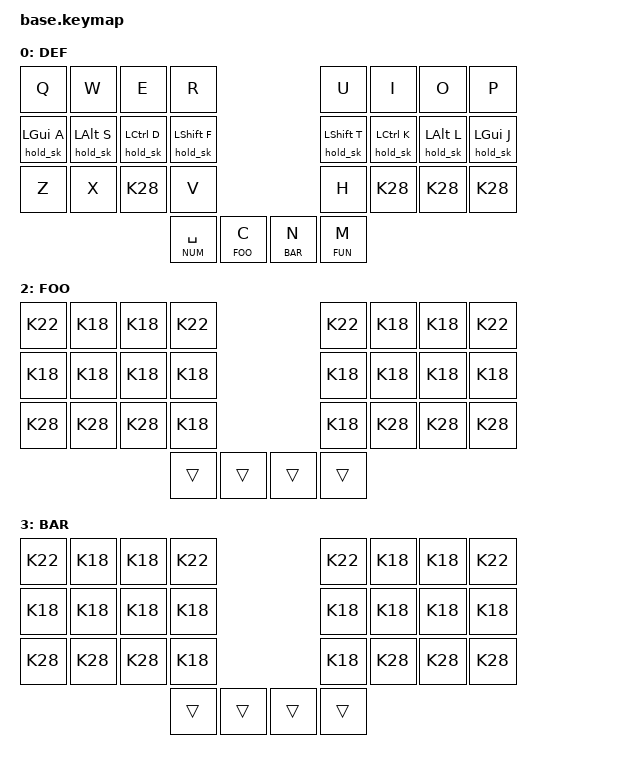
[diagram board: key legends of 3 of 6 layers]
// This file is automatically generated by sh from config/base.keymap

//╭─────────────╮   ╭─────────────╮   ╭─────────────┬───┬─────────────╮   ╭─────────────╮   ╭─────────────╮                                 ╭─────────────╮   ╭─────────────╮   ╭─────────────┬───┬─────────────╮   ╭─────────────╮   ╭─────────────╮
//                   K22               K18               K18               K22                                                                                 K22               K18               K18               K22                  
//├─────────────┤   ╰─────────────╯   ├─────────────┼───┼─────────────┤   ╰─────────────╯   ├─────────────┤                                 ├─────────────┤   ╰─────────────╯   ├─────────────┼───┼─────────────┤   ╰─────────────╯   ├─────────────┤
//├─────────────┤   ╭─────────────┬───┼─────────────┼───┼─────────────┼───┬─────────────╮   ├─────────────┤                                 ├─────────────┤   ╭─────────────┬───┼─────────────┼───┼─────────────┼───┬─────────────╮   ├─────────────┤
//                   K18               K18               K18               K18                                                                                 K18               K18               K18               K18                  
//├─────────────┤   ╰─────────────┴───┴─────────────┴───┴─────────────┴───┼─────────────┤   ├─────────────┤                                 ├─────────────┤   ├─────────────┼───┴─────────────┴───┴─────────────┴───┴─────────────╯   ├─────────────┤
//├─────────────┤   ╭─────────────┬───┬─────────────┬───┬─────────────╮   ├─────────────┤   ├─────────────┤                                 ├─────────────┤   ├─────────────┤   ╭─────────────┬───┬─────────────┬───┬─────────────╮   ├─────────────┤
//                   K28               K28               K28               K18                                                                                 K18               K28               K28               K28                  
//╰─────────────╯   ╰─────────────┴───┴─────────────┴───┴─────────────╯   ╰─────────────╯   ╰─────────────╯                                 ╰─────────────╯   ╰─────────────╯   ╰─────────────┴───┴─────────────┴───┴─────────────╯   ╰─────────────╯
//                                                                        ╭─────────────┬───┬─────────────╮ ╭─────────────────────────────╮ ╭─────────────┬───┬─────────────╮
//                                                                         K18               K18                                             K18               K18
//                                                                        ╰─────────────┴───┴─────────────╯ ╰─────────────────────────────╯ ╰─────────────┴───┴─────────────╯

// NOTE:
// 1. Use double tap instead of modify tap
// 2. Use sticky key instead of hold key
// 3. Never use two finger to type a single key

#include <behaviors.dtsi>
#include <dt-bindings/zmk/bt.h>
#include <dt-bindings/zmk/keys.h>
#include "../../../zmk-nodefree-config/helper.h"

//////////////////////////////
// Global Behavior
//////////////////////////////

#define TAP_MS       200
#define SHORT_TAP_MS 165

&sl {
    release-after-ms = <5000>;
    // quick-release;
};

&sk {
    release-after-ms = <5000>;
    // quick-release;
};

#define TAP_TAP(                                          \
    NAME       ,                                          \
    TAP_ACT    , TAP    ,                                 \
    TAPTAP_ACT , TAPTAP                                   \
    )                                                     \
    ZMK_BEHAVIOR(                                         \
        NAME,                                             \
        tap_dance,                                        \
        tapping-term-ms = <TAP_MS>;                       \
        bindings = <&TAP_ACT TAP> , <&TAPTAP_ACT TAPTAP>; \
    )

#define MAKE_HRM(                         \
    NAME ,                                \
    HOLD , TAP                            \
    )                                     \
    ZMK_BEHAVIOR(                         \
        NAME,                             \
        hold_tap,                         \
        flavor = "balanced";              \
        tapping-term-ms = <TAP_MS>;       \
        quick-tap-ms = <TAP_MS>;          \
        require-prior-idle-ms = <TAP_MS>; \
        bindings = <HOLD>, <TAP>;         \
    )
MAKE_HRM(hold_sk, &sk, &kp)

//////////////////////////////
// Layer Definition
//////////////////////////////

// 主副层，放置非功能键
#define DEF 0
#define NUM 1

// 零时层, 放置临时快捷键
#define FOO 2
#define BAR 3

// 功能层，放置功能快捷键
#define FUN 4

// 控制层
#define BLU 5

//////////////////////////////
// DEF
//////////////////////////////

////////////////////
// combos
////////////////////

ZMK_COMBO(esc         , &kp ESC             , LT3 LT2 , DEF, COMBO_TERM)
ZMK_COMBO(tab         , &kp TAB             , LM3 LM2 , DEF, COMBO_TERM)
ZMK_COMBO(bspc        , &kp BSPC            , RT2 RT3 , DEF, COMBO_TERM)
ZMK_COMBO(enter       , &kp ENTER           , RM2 RM3 , DEF, COMBO_TERM)

//////////

ZMK_COMBO(0           , &kp 0               , LT3 LM3 , DEF , COMBO_TERM)
ZMK_COMBO(y           , &kp Y               , LT2 LM2 , DEF , COMBO_TERM)
ZMK_COMBO(0           , &kp 0               , RT2 RM2 , DEF , COMBO_TERM)
ZMK_COMBO(0           , &kp 0               , RT3 RM3 , DEF , COMBO_TERM)

ZMK_COMBO(g           , &kp G               , LM1 LB1 , DEF , COMBO_TERM)
ZMK_COMBO(b           , &kp B               , RM1 RB1 , DEF , COMBO_TERM)

ZMK_COMBO(z           , &kp Z               , LH1 LH0 , DEF , COMBO_TERM)
ZMK_COMBO(x           , &kp X               , RH0 RH1 , DEF , COMBO_TERM)

////////////////////

ZMK_LAYER(DEF,
//╭─────────────╮   ╭─────────────╮   ╭─────────────┬───┬─────────────╮   ╭─────────────╮   ╭─────────────╮                                 ╭─────────────╮   ╭─────────────╮   ╭─────────────┬───┬─────────────╮   ╭─────────────╮   ╭─────────────╮
                     &kp Q             &kp W             &kp E             &kp R                                                                               &kp U             &kp I             &kp O             &kp P                
//                                                   Esc                                                                                                                                    Backspace
//├─────────────┤   ╰─────────────╯   ├─────────────┼───┼─────────────┤   ╰─────────────╯   ├─────────────┤                                 ├─────────────┤   ╰─────────────╯   ├─────────────┼───┼─────────────┤   ╰─────────────╯   ├─────────────┤
//                                          CMB                Y                                                                                                                      CMB               CMB
//├─────────────┤   ╭─────────────┬───┼─────────────┼───┼─────────────┼───┬─────────────╮   ├─────────────┤                                 ├─────────────┤   ╭─────────────┬───┼─────────────┼───┼─────────────┼───┬─────────────╮   ├─────────────┤
                     &hold_sk LGUI A   &hold_sk LALT S   &hold_sk LCTRL D  &hold_sk LSHFT F                                                                    &hold_sk LSHFT T  &hold_sk LCTRL K  &hold_sk LALT L   &hold_sk LGUI J      
//                                                   TAB                                                                                                                                      Return
//├─────────────┤   ╰─────────────┴───┴─────────────┴───┴─────────────┴───┼─────────────┤   ├─────────────┤                                 ├─────────────┤   ├─────────────┼───┴─────────────┴───┴─────────────┴───┴─────────────╯   ├─────────────┤
//                                                                              CMB                                                                                  B
//├─────────────┤   ╭─────────────┬───┬─────────────┬───┬─────────────╮   ├─────────────┤   ├─────────────┤                                 ├─────────────┤   ├─────────────┤   ╭─────────────┬───┬─────────────┬───┬─────────────╮   ├─────────────┤
                     &kp Z             &kp X             K28               &kp V                                                                               &kp H             K28               K28               K28                  
//╰─────────────╯   ╰─────────────┴───┴─────────────┴───┴─────────────╯   ╰─────────────╯   ╰─────────────╯                                 ╰─────────────╯   ╰─────────────╯   ╰─────────────┴───┴─────────────┴───┴─────────────╯   ╰─────────────╯
//                                                                        ╭─────────────┬───┬─────────────╮ ╭─────────────────────────────╮ ╭─────────────┬───┬─────────────╮
                                                                           &lt NUM SPACE     &lt FOO C                                       &lt BAR N         &lt FUN M
//                                                                        ╰─────────────┴───┴─────────────╯ ╰─────────────────────────────╯ ╰─────────────┴───┴─────────────╯
//                                                                                        Z                                                                 X
)

//////////////////////////////
// NUM
//////////////////////////////

//      NAME        , TAP_ACT , TAP      , TAPTAP_ACT , TAPTAP
TAP_TAP(comma_semi  , kp      , COMMA    , kp         , SEMI     ) // , (б) / ; (ж)
TAP_TAP(dot_colon   , kp      , DOT      , kp         , COLON    ) // . (ю) / :
TAP_TAP(excl_qmark  , kp      , EXCL     , kp         , QMARK    ) // !     / ?
TAP_TAP(apos_aposs  , kp      , APOS     , kp         , LS(APOS) ) // ' (э) / "
TAP_TAP(minus_plus  , kp      , MINUS    , kp         , PLUS     ) // -     / +
TAP_TAP(fslh_star   , kp      , FSLH     , kp         , STAR     ) // /     / *
TAP_TAP(dllr_caret  , kp      , DLLR     , kp         , CARET    ) // $     / ^
TAP_TAP(amps_pipe   , kp      , AMPS     , kp         , PIPE     ) // &     / |
TAP_TAP(under_equal , kp      , UNDER    , kp         , EQUAL    ) // _     / =
TAP_TAP(tilde_grave , kp      , TILDE    , kp         , GRAVE    ) // ~     / `
TAP_TAP(bslh_at     , kp      , BSLH     , kp         , AT       ) // \ (ё) / @
TAP_TAP(hash_prcnt  , kp      , HASH     , kp         , PRCNT    ) // #     / %
TAP_TAP(lt_gt       , kp      , LT       , kp         , GT       ) // <     / >
TAP_TAP(lpar_rpar   , kp      , LPAR     , kp         , RPAR     ) // (     / )
TAP_TAP(lbkt_rbkt   , kp      , LBKT     , kp         , RBKT     ) // [ (х) / ] (ъ)
TAP_TAP(lbrc_rbrc   , kp      , LBRC     , kp         , RBRC     ) // {     / }

////////////////////
// combos
////////////////////

ZMK_COMBO(lt_gt        , &lt_gt             , LT3 LT2 , NUM , COMBO_TERM)
ZMK_COMBO(lpar_rpar    , &lpar_rpar         , LM3 LM2 , NUM , COMBO_TERM)
ZMK_COMBO(lbkt_rbkt    , &lbkt_rbkt         , RT2 RT3 , NUM , COMBO_TERM)
ZMK_COMBO(lbrc_rbrc    , &lbrc_rbrc         , RM2 RM3 , NUM , COMBO_TERM)

//////////

ZMK_COMBO(tilde_grave  , &tilde_grave       , LT3 LM3 , NUM , COMBO_TERM)
ZMK_COMBO(under_equal  , &under_equal       , LT2 LM2 , NUM , COMBO_TERM)
ZMK_COMBO(dllr_caret   , &dllr_caret        , RT2 RM2 , NUM , COMBO_TERM)
ZMK_COMBO(amps_pipe    , &amps_pipe         , RT3 RM3 , NUM , COMBO_TERM)

ZMK_COMBO(hash_prcnt   , &hash_prcnt        , LM1 LB1 , NUM , COMBO_TERM)
ZMK_COMBO(bslh_at      , &bslh_at           , RM1 RB1 , NUM , COMBO_TERM)

ZMK_COMBO(0            , &kp 0              , LH1 LH0 , DEF , COMBO_TERM)
ZMK_COMBO(0            , &kp 0              , RH0 RH1 , DEF , COMBO_TERM)

////////////////////

TAP_TAP(n1          , kp      , N1       , kp         , LT       )
TAP_TAP(n2          , kp      , N2       , kp         , GT       )
TAP_TAP(n3          , kp      , N3       , kp         , LPAR     )
TAP_TAP(n4          , kp      , N4       , kp         , RPAR     )
TAP_TAP(n5          , kp      , N5       , kp         , APOS     )
TAP_TAP(n6          , kp      , N6       , kp         , LS(APOS) )
TAP_TAP(n7          , kp      , N7       , kp         , LBKT     )
TAP_TAP(n8          , kp      , N8       , kp         , RBKT     )
TAP_TAP(n9          , kp      , N9       , kp         , LBRC     )
TAP_TAP(n0          , kp      , N0       , kp         , RBRC     )

ZMK_LAYER(NUM,
//╭─────────────╮   ╭─────────────╮   ╭─────────────┬───┬─────────────╮   ╭─────────────╮   ╭─────────────╮                                 ╭─────────────╮   ╭─────────────╮   ╭─────────────┬───┬─────────────╮   ╭─────────────╮   ╭─────────────╮
                     K22               &minus_plus       &fslh_star        K22                                                                                 K22               &excl_qmark       &apos_aposs       K22                  
//                                                  < / >                                                                                                                                 [ (х) / ] (ъ)  э
//├─────────────┤   ╰─────────────╯   ├─────────────┼───┼─────────────┤   ╰─────────────╯   ├─────────────┤                                 ├─────────────┤   ╰─────────────╯   ├─────────────┼───┼─────────────┤   ╰─────────────╯   ├─────────────┤
//                                         ~ / `             _ / =                                                                                                                   $ / ^             & / |
//├─────────────┤   ╭─────────────┬───┼─────────────┼───┼─────────────┼───┬─────────────╮   ├─────────────┤                                 ├─────────────┤   ╭─────────────┬───┼─────────────┼───┼─────────────┼───┬─────────────╮   ├─────────────┤
                     &n1               &n2               &n3               &n4                                                                                 &n7               &n8               &n9               &n0                  
//                                                  ( / )                                                                                                                                     { / }
//├─────────────┤   ╰─────────────┴───┴─────────────┴───┴─────────────┴───┼─────────────┤   ├─────────────┤                                 ├─────────────┤   ├─────────────┼───┴─────────────┴───┴─────────────┴───┴─────────────╯   ├─────────────┤
//                                                                             # / %                                                                           \ (ё) / @
//├─────────────┤   ╭─────────────┬───┬─────────────┬───┬─────────────╮   ├─────────────┤   ├─────────────┤                                 ├─────────────┤   ├─────────────┤   ╭─────────────┬───┬─────────────┬───┬─────────────╮   ├─────────────┤
                     K28               K28               K28               &n5                                                                                 &n6               K28               K28               K28                  
//╰─────────────╯   ╰─────────────┴───┴─────────────┴───┴─────────────╯   ╰─────────────╯   ╰─────────────╯                                 ╰─────────────╯   ╰─────────────╯   ╰─────────────┴───┴─────────────┴───┴─────────────╯   ╰─────────────╯
//                                                                        ╭─────────────┬───┬─────────────╮ ╭─────────────────────────────╮ ╭─────────────┬───┬─────────────╮
                                                                           &trans            &trans                                          &comma_semi       &dot_colon
//                                                                        ╰─────────────┴───┴─────────────╯ ╰─────────────────────────────╯ ╰─────────────┴───┴─────────────╯
//                                                                                       CMB                                                               CMB
)

//////////////////////////////
// FOO
//////////////////////////////

ZMK_LAYER(FOO,
//╭─────────────╮   ╭─────────────╮   ╭─────────────┬───┬─────────────╮   ╭─────────────╮   ╭─────────────╮                                 ╭─────────────╮   ╭─────────────╮   ╭─────────────┬───┬─────────────╮   ╭─────────────╮   ╭─────────────╮
                     K22               K18               K18               K22                                                                                 K22               K18               K18               K22                  
//├─────────────┤   ╰─────────────╯   ├─────────────┼───┼─────────────┤   ╰─────────────╯   ├─────────────┤                                 ├─────────────┤   ╰─────────────╯   ├─────────────┼───┼─────────────┤   ╰─────────────╯   ├─────────────┤
//├─────────────┤   ╭─────────────┬───┼─────────────┼───┼─────────────┼───┬─────────────╮   ├─────────────┤                                 ├─────────────┤   ╭─────────────┬───┼─────────────┼───┼─────────────┼───┬─────────────╮   ├─────────────┤
                     K18               K18               K18               K18                                                                                 K18               K18               K18               K18                  
//├─────────────┤   ╰─────────────┴───┴─────────────┴───┴─────────────┴───┼─────────────┤   ├─────────────┤                                 ├─────────────┤   ├─────────────┼───┴─────────────┴───┴─────────────┴───┴─────────────╯   ├─────────────┤
//├─────────────┤   ╭─────────────┬───┬─────────────┬───┬─────────────╮   ├─────────────┤   ├─────────────┤                                 ├─────────────┤   ├─────────────┤   ╭─────────────┬───┬─────────────┬───┬─────────────╮   ├─────────────┤
                     K28               K28               K28               K18                                                                                 K18               K28               K28               K28                  
//╰─────────────╯   ╰─────────────┴───┴─────────────┴───┴─────────────╯   ╰─────────────╯   ╰─────────────╯                                 ╰─────────────╯   ╰─────────────╯   ╰─────────────┴───┴─────────────┴───┴─────────────╯   ╰─────────────╯
//                                                                        ╭─────────────┬───┬─────────────╮ ╭─────────────────────────────╮ ╭─────────────┬───┬─────────────╮
                                                                           &trans            &trans                                          &trans            &trans
//                                                                        ╰─────────────┴───┴─────────────╯ ╰─────────────────────────────╯ ╰─────────────┴───┴─────────────╯
)

//////////////////////////////
// BAR
//////////////////////////////

ZMK_LAYER(BAR,
//╭─────────────╮   ╭─────────────╮   ╭─────────────┬───┬─────────────╮   ╭─────────────╮   ╭─────────────╮                                 ╭─────────────╮   ╭─────────────╮   ╭─────────────┬───┬─────────────╮   ╭─────────────╮   ╭─────────────╮
                     K22               K18               K18               K22                                                                                 K22               K18               K18               K22                  
//├─────────────┤   ╰─────────────╯   ├─────────────┼───┼─────────────┤   ╰─────────────╯   ├─────────────┤                                 ├─────────────┤   ╰─────────────╯   ├─────────────┼───┼─────────────┤   ╰─────────────╯   ├─────────────┤
//├─────────────┤   ╭─────────────┬───┼─────────────┼───┼─────────────┼───┬─────────────╮   ├─────────────┤                                 ├─────────────┤   ╭─────────────┬───┼─────────────┼───┼─────────────┼───┬─────────────╮   ├─────────────┤
                     K18               K18               K18               K18                                                                                 K18               K18               K18               K18                  
//├─────────────┤   ╰─────────────┴───┴─────────────┴───┴─────────────┴───┼─────────────┤   ├─────────────┤                                 ├─────────────┤   ├─────────────┼───┴─────────────┴───┴─────────────┴───┴─────────────╯   ├─────────────┤
//├─────────────┤   ╭─────────────┬───┬─────────────┬───┬─────────────╮   ├─────────────┤   ├─────────────┤                                 ├─────────────┤   ├─────────────┤   ╭─────────────┬───┬─────────────┬───┬─────────────╮   ├─────────────┤
                     K28               K28               K28               K18                                                                                 K18               K28               K28               K28                  
//╰─────────────╯   ╰─────────────┴───┴─────────────┴───┴─────────────╯   ╰─────────────╯   ╰─────────────╯                                 ╰─────────────╯   ╰─────────────╯   ╰─────────────┴───┴─────────────┴───┴─────────────╯   ╰─────────────╯
//                                                                        ╭─────────────┬───┬─────────────╮ ╭─────────────────────────────╮ ╭─────────────┬───┬─────────────╮
                                                                           &trans            &trans                                          &trans            &trans
//                                                                        ╰─────────────┴───┴─────────────╯ ╰─────────────────────────────╯ ╰─────────────┴───┴─────────────╯
)

//////////////////////////////
// FUN
//////////////////////////////

//      NAME        , TAP_ACT , TAP      , TAPTAP_ACT , TAPTAP
TAP_TAP(vol_prev_pp , kp      , C_PREV   , kp         , C_PP   )
TAP_TAP(vol_dn_mute , kp      , C_VOL_DN , kp         , C_MUTE )

TAP_TAP(left_home   , kp      , LEFT     , kp         , HOME   )
TAP_TAP(down_pg_dn  , kp      , DOWN     , kp         , PG_DN  )
TAP_TAP(up_pg_up    , kp      , UP       , kp         , PG_UP  )
TAP_TAP(right_end   , kp      , RIGHT    , kp         , END    )

ZMK_LAYER(FUN,
//╭─────────────╮   ╭─────────────╮   ╭─────────────┬───┬─────────────╮   ╭─────────────╮   ╭─────────────╮                                 ╭─────────────╮   ╭─────────────╮   ╭─────────────┬───┬─────────────╮   ╭─────────────╮   ╭─────────────╮
                     K22               &kp C_BRI_UP      &kp C_VOL_UP      K22                                                                                 K22               K18               K18               K22                  
//├─────────────┤   ╰─────────────╯   ├─────────────┼───┼─────────────┤   ╰─────────────╯   ├─────────────┤                                 ├─────────────┤   ╰─────────────╯   ├─────────────┼───┼─────────────┤   ╰─────────────╯   ├─────────────┤
//├─────────────┤   ╭─────────────┬───┼─────────────┼───┼─────────────┼───┬─────────────╮   ├─────────────┤                                 ├─────────────┤   ╭─────────────┬───┼─────────────┼───┼─────────────┼───┬─────────────╮   ├─────────────┤
                     K18               &kp C_BRI_DN      &vol_dn_mute      &kp C_NEXT                                                                          &up_pg_up         &left_home        &right_end        &kp LG(LC(Q))        
//├─────────────┤   ╰─────────────┴───┴─────────────┴───┴─────────────┴───┼─────────────┤   ├─────────────┤                                 ├─────────────┤   ├─────────────┼───┴─────────────┴───┴─────────────┴───┴─────────────╯   ├─────────────┤
//├─────────────┤   ╭─────────────┬───┬─────────────┬───┬─────────────╮   ├─────────────┤   ├─────────────┤                                 ├─────────────┤   ├─────────────┤   ╭─────────────┬───┬─────────────┬───┬─────────────╮   ├─────────────┤
                     K28               K28               K28               &vol_prev_pp                                                                        &down_pg_dn       K28               K28               K28                  
//╰─────────────╯   ╰─────────────┴───┴─────────────┴───┴─────────────╯   ╰─────────────╯   ╰─────────────╯                                 ╰─────────────╯   ╰─────────────╯   ╰─────────────┴───┴─────────────┴───┴─────────────╯   ╰─────────────╯
//                                                                        ╭─────────────┬───┬─────────────╮ ╭─────────────────────────────╮ ╭─────────────┬───┬─────────────╮
                                                                           &trans            &trans                                          &trans            &trans
//                                                                        ╰─────────────┴───┴─────────────╯ ╰─────────────────────────────╯ ╰─────────────┴───┴─────────────╯
)

//////////////////////////////
// BLU
//////////////////////////////

ZMK_CONDITIONAL_LAYER(FOO BAR, BLU)

ZMK_LAYER(BLU,
//╭─────────────╮   ╭─────────────╮   ╭─────────────┬───┬─────────────╮   ╭─────────────╮   ╭─────────────╮                                 ╭─────────────╮   ╭─────────────╮   ╭─────────────┬───┬─────────────╮   ╭─────────────╮   ╭─────────────╮
                     K22               &bt BT_CLR        &bootloader       K22                                                                                 K22               &bootloader       &bt BT_CLR        K22                  
//├─────────────┤   ╰─────────────╯   ├─────────────┼───┼─────────────┤   ╰─────────────╯   ├─────────────┤                                 ├─────────────┤   ╰─────────────╯   ├─────────────┼───┼─────────────┤   ╰─────────────╯   ├─────────────┤
//├─────────────┤   ╭─────────────┬───┼─────────────┼───┼─────────────┼───┬─────────────╮   ├─────────────┤                                 ├─────────────┤   ╭─────────────┬───┼─────────────┼───┼─────────────┼───┬─────────────╮   ├─────────────┤
                     &bt BT_SEL 1      &bt BT_SEL 2      &bt BT_SEL 3      &bt BT_SEL 4                                                                        &bt BT_SEL 7      &bt BT_SEL 8      &bt BT_SEL 9      &bt BT_SEL 0         
//├─────────────┤   ╰─────────────┴───┴─────────────┴───┴─────────────┴───┼─────────────┤   ├─────────────┤                                 ├─────────────┤   ├─────────────┼───┴─────────────┴───┴─────────────┴───┴─────────────╯   ├─────────────┤
//├─────────────┤   ╭─────────────┬───┬─────────────┬───┬─────────────╮   ├─────────────┤   ├─────────────┤                                 ├─────────────┤   ├─────────────┤   ╭─────────────┬───┬─────────────┬───┬─────────────╮   ├─────────────┤
                     &kp N0            K28               K28               &bt BT_SEL 5                                                                        &bt BT_SEL 6      K28               K28               K28                  
//╰─────────────╯   ╰─────────────┴───┴─────────────┴───┴─────────────╯   ╰─────────────╯   ╰─────────────╯                                 ╰─────────────╯   ╰─────────────╯   ╰─────────────┴───┴─────────────┴───┴─────────────╯   ╰─────────────╯
//                                                                        ╭─────────────┬───┬─────────────╮ ╭─────────────────────────────╮ ╭─────────────┬───┬─────────────╮
                                                                           &trans            &trans                                          &trans            &trans
//                                                                        ╰─────────────┴───┴─────────────╯ ╰─────────────────────────────╯ ╰─────────────┴───┴─────────────╯
)
